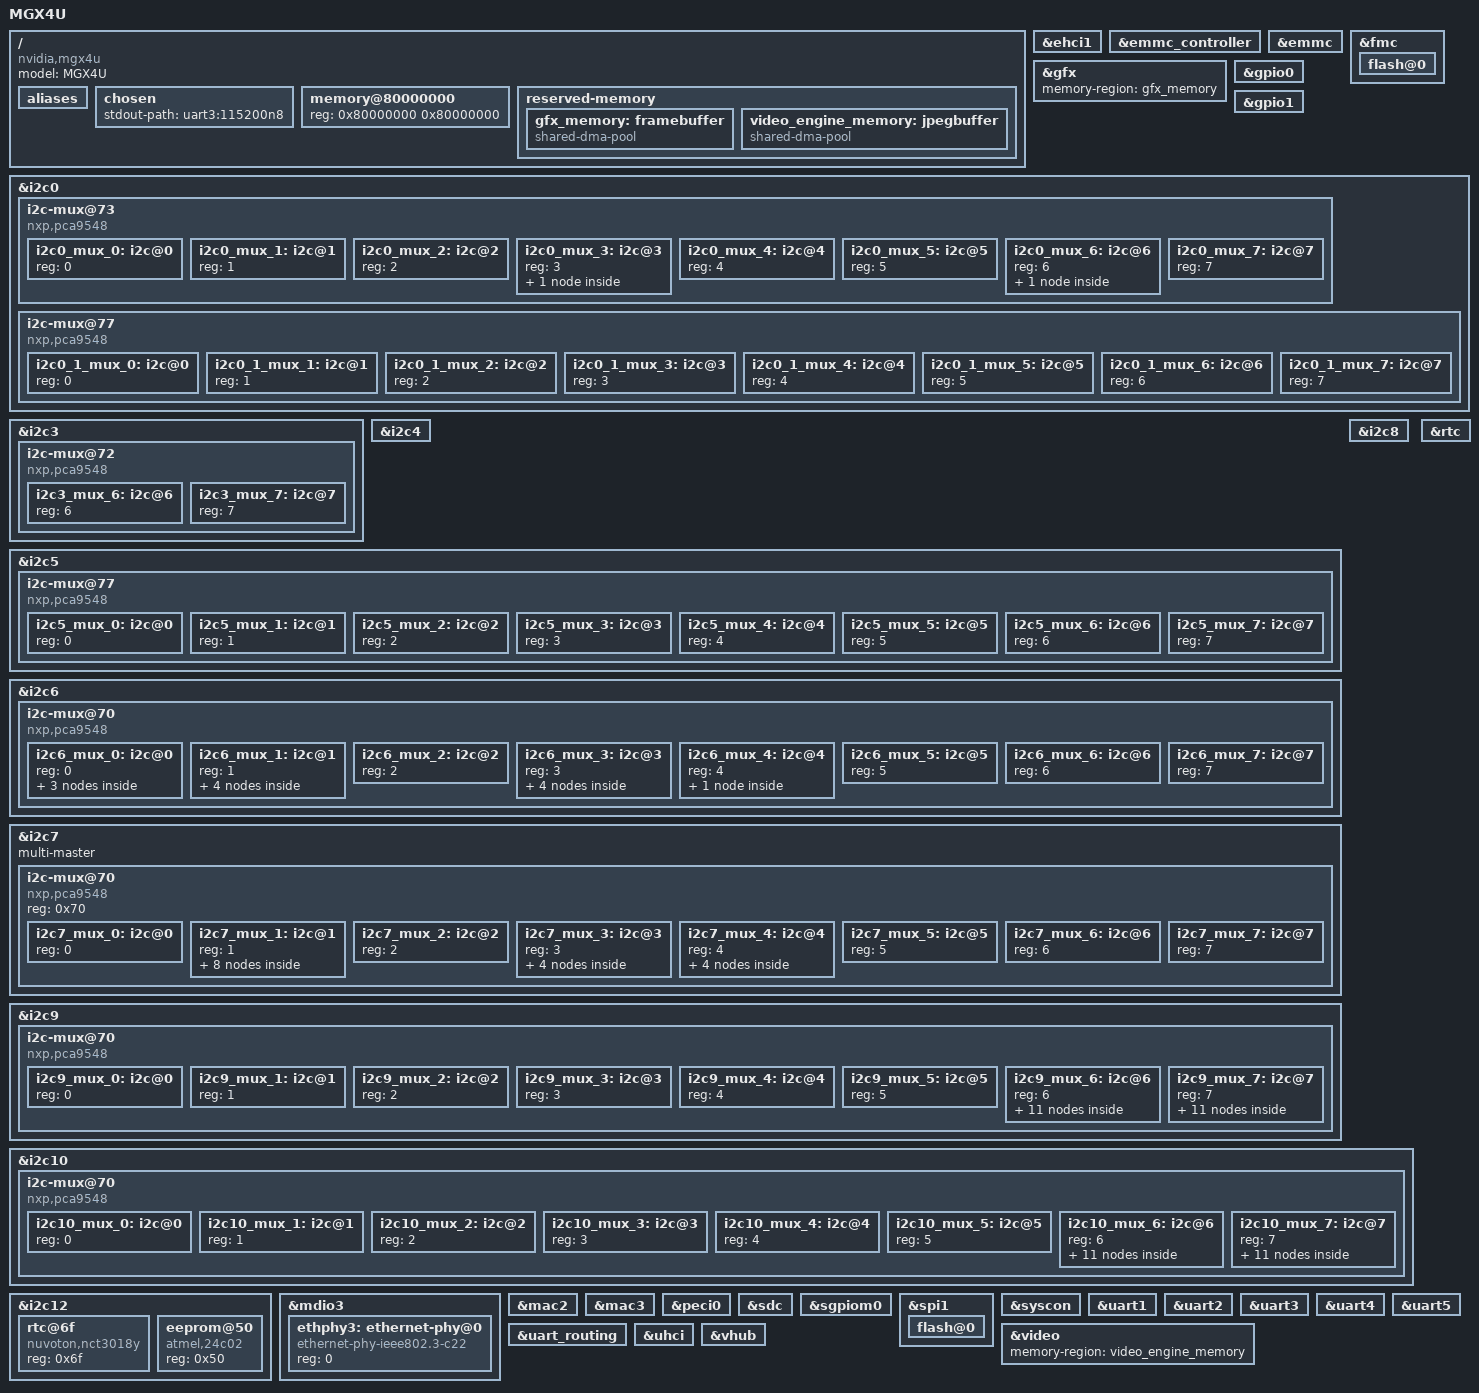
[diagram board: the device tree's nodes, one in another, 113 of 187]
// SPDX-License-Identifier: GPL-2.0

/dts-v1/;

#include "aspeed-g6.dtsi"
#include <dt-bindings/gpio/aspeed-gpio.h>
#include <dt-bindings/i2c/i2c.h>

/ {
	model = "MGX4U";
	compatible = "nvidia,mgx4u", "aspeed,ast2600";

	aliases {
		serial0 = &uart1;
		serial1 = &uart2;
		serial2 = &uart3;
		serial3 = &uart4;
		serial4 = &uart5;

		i2c16 = &i2c5_mux_0;
		i2c17 = &i2c5_mux_1;
		i2c18 = &i2c5_mux_2;
		i2c19 = &i2c5_mux_3;
		i2c20 = &i2c5_mux_4;
		i2c21 = &i2c5_mux_5;
		i2c22 = &i2c5_mux_6;
		i2c23 = &i2c5_mux_7;

		i2c24 = &i2c6_mux_0;
		i2c25 = &i2c6_mux_1;
		i2c26 = &i2c6_mux_2;
		i2c27 = &i2c6_mux_3;
		i2c28 = &i2c6_mux_4;
		i2c29 = &i2c6_mux_5;
		i2c30 = &i2c6_mux_6;
		i2c31 = &i2c6_mux_7;

		i2c32 = &i2c7_1_mux_0;
		i2c33 = &i2c7_1_mux_1;
		i2c35 = &i2c7_1_mux_2;
		i2c36 = &i2c7_1_mux_3;
		i2c37 = &i2c7_mux_0;
		i2c38 = &i2c7_mux_1;
		i2c39 = &i2c7_mux_2;
		i2c40 = &i2c7_mux_3;
		i2c41 = &i2c7_mux_4;
		i2c42 = &i2c7_mux_5;
		i2c43 = &i2c7_mux_6;
		i2c44 = &i2c7_mux_7;

		i2c45 = &i2c0_mux_0;
		i2c46 = &i2c0_mux_1;
		i2c47 = &i2c0_mux_2;
		i2c48 = &i2c0_mux_3;
		i2c49 = &i2c0_mux_4;
		i2c50 = &i2c0_mux_5;
		i2c51 = &i2c0_mux_6;
		i2c52 = &i2c0_mux_7;

		i2c53 = &i2c0_1_mux_0;
		i2c54 = &i2c0_1_mux_1;
		i2c55 = &i2c0_1_mux_2;
		i2c56 = &i2c0_1_mux_3;
		i2c57 = &i2c0_1_mux_4;
		i2c58 = &i2c0_1_mux_5;
		i2c59 = &i2c0_1_mux_6;
		i2c60 = &i2c0_1_mux_7;

		i2c61 = &i2c3_mux_6;
		i2c62 = &i2c3_mux_7;

		i2c63 = &i2c9_mux_0;
		i2c64 = &i2c9_mux_1;
		i2c65 = &i2c9_mux_2;
		i2c66 = &i2c9_mux_3;
		i2c67 = &i2c9_mux_4;
		i2c68 = &i2c9_mux_5;
		i2c69 = &i2c9_mux_6;
		i2c70 = &i2c9_mux_7;

		i2c71 = &i2c9_mux_6_2;
		i2c72 = &i2c9_mux_6_3;
		i2c73 = &i2c9_mux_7_2;
		i2c74 = &i2c9_mux_7_3;
		i2c75 = &i2c10_mux_6_2;
		i2c76 = &i2c10_mux_6_3;
		i2c77 = &i2c10_mux_7_2;
		i2c78 = &i2c10_mux_7_3;
	};

	chosen {
		stdout-path = "uart3:115200n8";
	};

	memory@80000000 {
		device_type = "memory";
		reg = <0x80000000 0x80000000>;
	};

	reserved-memory {
		#address-cells = <1>;
		#size-cells = <1>;
		ranges;

		gfx_memory: framebuffer {
			size = <0x01000000>;
			alignment = <0x01000000>;
			compatible = "shared-dma-pool";
			reusable;
		};

		video_engine_memory: jpegbuffer {
			size = <0x02000000>;	/* 32M */
			alignment = <0x01000000>;
			compatible = "shared-dma-pool";
			reusable;
		};
	};
};

&ehci1 {
	status = "okay";
};

&emmc_controller {
	status = "okay";
};

&emmc {
	non-removable;
	bus-width = <4>;
	max-frequency = <100000000>;
	clk-phase-mmc-hs200 = <9>, <225>;
};

&fmc {
	status = "okay";

	flash@0 {
		status = "okay";
		m25p,fast-read;
		label = "bmc";
		spi-rx-bus-width = <4>;
		spi-tx-bus-width = <4>;
		spi-max-frequency = <50000000>;
#include "openbmc-flash-layout-128.dtsi"
	};
};

&gfx {
	memory-region = <&gfx_memory>;
	status = "okay";
};

&gpio0 {
	gpio-line-names =
	/*A0-A7*/ "","","","","","","","",
	/*B0-B7*/ "","","","","","","","RST_BMC_8211F_N",
	/*C0-C7*/ "","","","","","","","",
	/*D0-D7*/ "","","","","","","","",
	/*E0-E7*/ "","","","","","","","",
	/*F0-F7*/ "","RST_BIOSROM_1_BMC_N","","RST_SPI_PFRM1_R_N","","","SPI_BIOS_MUX_SEL","",
	/*G0-G7*/ "","","","","","","","",
	/*H0-H7*/ "","","","","","","","",
	/*I0-I7*/ "","","","","","","","",
	/*J0-J7*/ "","","","","","","","",
	/*K0-K7*/ "","","","","","","","",
	/*L0-L7*/ "","","","","","","","",
	/*M0-M7*/ "","","","","","","","",
	/*N0-N7*/ "","","","","","","","",
	/*O0-O7*/ "","","","","","","","",
	/*P0-P7*/ "","","","","","","","",
	/*Q0-Q7*/ "","","","","","","","",
	/*R0-R7*/ "","","","","","","","",
	/*S0-S7*/ "","","","","","","","",
	/*T0-T7*/ "","","","","","","","",
	/*U0-U7*/ "","","","","","","","",
	/*V0-V7*/ "","","SCM_HPM_STBY_RST_N","","SCM_HPM_STBY_EN","","","",
	/*W0-W7*/ "","","","","","","","",
	/*X0-X7*/ "","","","","","","","",
	/*Y0-Y7*/ "","","","","","","","",
	/*Z0-Z7*/ "","","","","","","","";
	status = "okay";
};

&gpio1 {
	gpio-line-names =
	/*18A0-18A7*/ "","","","","","","","",
	/*18B0-18B7*/ "","","","","SW_MAIN_EN","HOST_GLOBAL_WP_N","","",
	/*18C0-18C7*/ "","","","","","","","",
	/*18D0-18D7*/ "","","","","","","","",
	/*18E0-18E3*/ "","","","";
	status = "okay";
};

&i2c0 {
	status = "okay";

	i2c-mux@73 {
		compatible = "nxp,pca9548";
		reg = <0x73>;
		#address-cells = <1>;
		#size-cells = <0>;
		i2c-mux-idle-disconnect;

		i2c0_mux_0: i2c@0 {
			reg = <0>;
			#address-cells = <1>;
			#size-cells = <0>;
		};

		i2c0_mux_1: i2c@1 {
			#address-cells = <1>;
			#size-cells = <0>;
			reg = <1>;
		};

		i2c0_mux_2: i2c@2 {
			reg = <2>;
			#address-cells = <1>;
			#size-cells = <0>;
		};

		i2c0_mux_3: i2c@3 {
			reg = <3>;
			#address-cells = <1>;
			#size-cells = <0>;

			eeprom@51 {
				compatible = "atmel,24c02";
				reg = <0x51>;
			};
		};

		i2c0_mux_4: i2c@4 {
			reg = <4>;
			#address-cells = <1>;
			#size-cells = <0>;
		};

		i2c0_mux_5: i2c@5 {
			reg = <5>;
			#address-cells = <1>;
			#size-cells = <0>;
		};

		i2c0_mux_6: i2c@6 {
			reg = <6>;
			#address-cells = <1>;
			#size-cells = <0>;

			temperature-sensor@4c {
				compatible = "ti,tmp75";
				reg = <0x4c>;
			};
		};

		i2c0_mux_7: i2c@7 {
			reg = <7>;
			#address-cells = <1>;
			#size-cells = <0>;
		};
	};

	i2c-mux@77 {
		compatible = "nxp,pca9548";
		reg = <0x77>;
		#address-cells = <1>;
		#size-cells = <0>;
		i2c-mux-idle-disconnect;

		i2c0_1_mux_0: i2c@0 {
			reg = <0>;
			#address-cells = <1>;
			#size-cells = <0>;
		};

		i2c0_1_mux_1: i2c@1 {
			reg = <1>;
			#address-cells = <1>;
			#size-cells = <0>;
		};

		i2c0_1_mux_2: i2c@2 {
			reg = <2>;
			#address-cells = <1>;
			#size-cells = <0>;
		};

		i2c0_1_mux_3: i2c@3 {
			reg = <3>;
			#address-cells = <1>;
			#size-cells = <0>;
		};

		i2c0_1_mux_4: i2c@4 {
			reg = <4>;
			#address-cells = <1>;
			#size-cells = <0>;
		};

		i2c0_1_mux_5: i2c@5 {
			reg = <5>;
			#address-cells = <1>;
			#size-cells = <0>;
		};

		i2c0_1_mux_6: i2c@6 {
			reg = <6>;
			#address-cells = <1>;
			#size-cells = <0>;
		};

		i2c0_1_mux_7: i2c@7 {
			reg = <7>;
			#address-cells = <1>;
			#size-cells = <0>;
		};
	};
};


&i2c3 {
	status = "okay";

	i2c-mux@72 {
		compatible = "nxp,pca9548";
		reg = <0x72>;
		#address-cells = <1>;
		#size-cells = <0>;
		i2c-mux-idle-disconnect;

		i2c3_mux_6: i2c@6 {
			reg = <6>;
			#address-cells = <1>;
			#size-cells = <0>;
		};

		i2c3_mux_7: i2c@7 {
			reg = <7>;
			#address-cells = <1>;
			#size-cells = <0>;
		};
	};
};

&i2c4 {
	status = "okay";
};

&i2c5 {
	status = "okay";

	i2c-mux@77 {
		compatible = "nxp,pca9548";
		reg = <0x77>;
		#address-cells = <1>;
		#size-cells = <0>;
		i2c-mux-idle-disconnect;

		i2c5_mux_0: i2c@0 {
			reg = <0>;
			#address-cells = <1>;
			#size-cells = <0>;
		};

		i2c5_mux_1: i2c@1 {
			reg = <1>;
			#address-cells = <1>;
			#size-cells = <0>;
		};

		i2c5_mux_2: i2c@2 {
			reg = <2>;
			#address-cells = <1>;
			#size-cells = <0>;
		};

		i2c5_mux_3: i2c@3 {
			reg = <3>;
			#address-cells = <1>;
			#size-cells = <0>;
		};

		i2c5_mux_4: i2c@4 {
			reg = <4>;
			#address-cells = <1>;
			#size-cells = <0>;
		};

		i2c5_mux_5: i2c@5 {
			reg = <5>;
			#address-cells = <1>;
			#size-cells = <0>;
		};

		i2c5_mux_6: i2c@6 {
			reg = <6>;
			#address-cells = <1>;
			#size-cells = <0>;
		};

		i2c5_mux_7: i2c@7 {
			reg = <7>;
			#address-cells = <1>;
			#size-cells = <0>;
		};
	};
};

&i2c6 {
	status = "okay";

	i2c-mux@70 {
		reg = <0x70>;
		compatible = "nxp,pca9548";
		#address-cells = <1>;
		#size-cells = <0>;
		i2c-mux-idle-disconnect;

		i2c6_mux_0: i2c@0 {
			reg = <0>;
			#address-cells = <1>;
			#size-cells = <0>;

			temperature-sensor@4a {
				compatible = "ti,tmp75";
				reg = <0x4a>;
			};

			temperature-sensor@4b {
				compatible = "ti,tmp75";
				reg = <0x4b>;
			};

			eeprom@51 {
				compatible = "atmel,24c64";
				reg = <0x51>;
				pagesize = <32>;
			};
		};

		i2c6_mux_1: i2c@1 {
			reg = <1>;
			#address-cells = <1>;
			#size-cells = <0>;

			/*fan controller 0*/
			fan-controller@20 {
				compatible = "maxim,max31790";
				reg = <0x20>;
			};

			/*fan controller 1*/
			fan-controller@21 {
				compatible = "maxim,max31790";
				reg = <0x21>;
			};

			eeprom@57 {
				compatible = "atmel,24c64";
				reg = <0x57>;
				pagesize = <32>;
			};

			hpmfanio: gpio@27 {
				compatible = "nxp,pca9555";
				reg = <0x27>;
				gpio-controller;
				#gpio-cells = <2>;
				interrupt-controller;
				#interrupt-cells = <2>;
				interrupt-parent = <&gpio0>;
				interrupts = <11 0>;
				gpio-line-names =
						"HPM_FAN1_INSTALL", "HPM_FAN2_INSTALL",
						"HPM_FAN3_INSTALL", "HPM_FAN4_INSTALL",
						"HPM_FAN5_INSTALL", "",
						"","";
			};
		 };

		 i2c6_mux_2: i2c@2 {
			reg = <2>;
			#address-cells = <1>;
			#size-cells = <0>;
		 };

		 i2c6_mux_3: i2c@3 {
			reg = <3>;
			#address-cells = <1>;
			#size-cells = <0>;

			/* 4056 fan board_EEPROM*/
			eeprom@57 {
				compatible = "atmel,24c64";
				reg = <0x57>;
				pagesize = <32>;
			};

			/*fan controller 0*/
			fan-controller@20 {
				compatible = "maxim,max31790";
				reg = <0x20>;
			};
			/*fan controller 1*/
			fan-controller@21 {
				compatible = "maxim,max31790";
				reg = <0x21>;
			};

			gpufanio: gpio@27 {
				compatible = "nxp,pca9555";
				reg = <0x27>;
				gpio-controller;
				#gpio-cells = <2>;
				interrupt-controller;
				#interrupt-cells = <2>;
				interrupt-parent = <&gpio0>;
				interrupts = <11 0>;
				gpio-line-names =
						"GPU_FAN1_INSTALL", "GPU_FAN2_INSTALL",
						"GPU_FAN3_INSTALL", "GPU_FAN4_INSTALL",
						"GPU_FAN5_INSTALL", "",
						"","";
			};
		 };

		i2c6_mux_4: i2c@4 {
			reg = <4>;
			#address-cells = <1>;
			#size-cells = <0>;

			/* IO board EEPROM*/
			eeprom@57 {
				compatible = "atmel,24c64";
				reg = <0x57>;
				pagesize = <32>;
			};
		};

		i2c6_mux_5: i2c@5 {
			reg = <5>;
			#address-cells = <1>;
			#size-cells = <0>;
		};

		i2c6_mux_6: i2c@6 {
			reg = <6>;
			#address-cells = <1>;
			#size-cells = <0>;
		};

		i2c6_mux_7: i2c@7 {
			reg = <7>;
			#address-cells = <1>;
			#size-cells = <0>;
		};
	};
};

&i2c7 {
	multi-master;
	status = "okay";

	i2c-mux@70 {
		compatible = "nxp,pca9548";
		reg = <0x70>;
		#address-cells = <1>;
		#size-cells = <0>;

		i2c7_mux_0: i2c@0 {
			reg = <0>;
			#address-cells = <1>;
			#size-cells = <0>;
		};

		i2c7_mux_1: i2c@1 {
			reg = <1>;
			#address-cells = <1>;
			#size-cells = <0>;

			i2c-mux@71 {
				compatible = "nxp,pca9545";
				reg = <0x71>;
				#address-cells = <1>;
				#size-cells = <0>;

				i2c7_1_mux_0: i2c@0 {
					reg = <0>;
					#address-cells = <1>;
					#size-cells = <0>;
				};

				i2c7_1_mux_1: i2c@1 {
					reg = <1>;
					#address-cells = <1>;
					#size-cells = <0>;

					eeprom@55 {
						compatible = "atmel,24c64";
						reg = <0x55>;
						pagesize = <32>;
					};

					eeprom@50 {
						compatible = "atmel,24c02";
						reg = <0x50>;
						pagesize = <32>;
					};

					eeprom@53 {
						compatible = "atmel,24c02";
						reg = <0x53>;
						pagesize = <32>;
					};
				};

				i2c7_1_mux_2: i2c@2 {
					reg = <2>;
					#address-cells = <1>;
					#size-cells = <0>;
				};

				i2c7_1_mux_3: i2c@3 {
					reg = <3>;
					#address-cells = <1>;
					#size-cells = <0>;
				};
			};
		};

		i2c7_mux_2: i2c@2 {
			reg = <2>;
			#address-cells = <1>;
			#size-cells = <0>;
		};

		i2c7_mux_3: i2c@3 {
			reg = <3>;
			#address-cells = <1>;
			#size-cells = <0>;

			/* XDPE19284B - CPU0 PVCCIN VR */
			regulator@60 {
				compatible = "infineon,xdpe152c4";
				reg = <0x60>;
			};

			/* XDPE19284B - CPU0 PVCCFA EHV FIVRA / PVCCINF_VR*/
			regulator@62 {
				compatible = "infineon,xdpe152c4";
				reg = <0x62>;
			};

			/* XDPE19284B - CPU0 PVCCA EHV PVCCIN VR */
			regulator@74 {
				compatible = "infineon,xdpe152c4";
				reg = <0x74>;
			};

			/* XDPE19284B - CPU0 PVVCCD0 & D1 VR */
			regulator@76 {
				compatible = "infineon,xdpe152c4";
				reg = <0x76>;
			};
		};

		i2c7_mux_4: i2c@4 {
			reg = <4>;
			#address-cells = <1>;
			#size-cells = <0>;

			/* XDPE19284B - CPU1 PVCCIN VR */
			regulator@60 {
				compatible = "infineon,xdpe152c4";
				reg = <0x60>;
			};

			/* XDPE19284B - CPU1 PVCCFA EHV FIVRA / PVCCINF_VR*/
			regulator@62 {
				compatible = "infineon,xdpe152c4";
				reg = <0x62>;
			};

			/* XDPE19284B - CPU1 PVCCA EHV PVCCIN VR */
			regulator@74 {
				compatible = "infineon,xdpe152c4";
				reg = <0x74>;
			};

			/* XDPE19284B - CPU1 PVVCCD0 & D1 VR */
			regulator@76 {
				compatible = "infineon,xdpe152c4";
				reg = <0x76>;
			};
		};

		i2c7_mux_5: i2c@5 {
			reg = <5>;
			#address-cells = <1>;
			#size-cells = <0>;
		};

		i2c7_mux_6: i2c@6 {
			reg = <6>;
			#address-cells = <1>;
			#size-cells = <0>;
		};

		i2c7_mux_7: i2c@7 {
			reg = <7>;
			#address-cells = <1>;
			#size-cells = <0>;
		};
	};
};

&i2c8 {
	status = "okay";
};

&i2c9 {
	status = "okay";

	i2c-mux@70 {
		compatible = "nxp,pca9548";
		reg = <0x70>;
		#address-cells = <1>;
		#size-cells = <0>;
		i2c-mux-idle-disconnect;

		i2c9_mux_0: i2c@0 {
			reg = <0>;
			#address-cells = <1>;
			#size-cells = <0>;
		};

		i2c9_mux_1: i2c@1 {
			reg = <1>;
			#address-cells = <1>;
			#size-cells = <0>;
		};

		i2c9_mux_2: i2c@2 {
			reg = <2>;
			#address-cells = <1>;
			#size-cells = <0>;
		};

		i2c9_mux_3: i2c@3 {
			reg = <3>;
			#address-cells = <1>;
			#size-cells = <0>;
		};

		i2c9_mux_4: i2c@4 {
			reg = <4>;
			#address-cells = <1>;
			#size-cells = <0>;
		};

		i2c9_mux_5: i2c@5 {
			reg = <5>;
			#address-cells = <1>;
			#size-cells = <0>;
		};

		i2c9_mux_6: i2c@6 {
			reg = <6>;
			#address-cells = <1>;
			#size-cells = <0>;

			eeprom@56 {
				compatible = "atmel,24c128";
				reg = <0x56>;
			};

			gpio@26 {
				compatible = "nxp,pca9555";
				reg = <0x26>;
				gpio-controller;
				#gpio-cells = <2>;
				gpio-line-names = "WP_QSPI_CX0", "RST_SEQ_CX0_L",
						  "BOOT_COMPLT_CX0", "FNP_CX0_L",
						  "WP_FRU_CX0", "OVT_SHUTDOWN_CX0",
						  "", "",
						  "", "",
						  "TMP_WARNING_CX0", "USB_HUB1_RST_L",
						  "I2C_SWITCH1_RESET", "MCU1_GPIO",
						  "MCU1_RST_N", "MCU1_RECOVERY_N";

			};

			i2c-mux@72 {
				compatible = "nxp,pca9546";
				reg = <0x72>;
				i2c-mux-idle-disconnect;
				#address-cells = <1>;
				#size-cells = <0>;

				i2c@0 {
					reg = <0>;
					#address-cells = <1>;
					#size-cells = <0>;
				};

				i2c@1 {
					reg = <1>;
					#address-cells = <1>;
					#size-cells = <0>;
				};

				i2c9_mux_6_2: i2c@2 {
					reg = <2>;
					#address-cells = <1>;
					#size-cells = <0>;

					gpio@20 {
						reg = <0x20>;
						gpio-controller;
						compatible = "nxp,pca6408";
						#gpio-cells = <2>;
						gpio-line-names = "GLOBAL_WP_0",
								  "OOB_RST_N_0",
								  "OOB_RECOVERY_0",
								  "MCU_RECOVERY_N_0",
								  "MCU_RST_N_0",
								  "MCU_BYPASS_N_0",
								  "SMBUS_FRU_EEPROM_WP_0",
								  "";
					};

					eeprom@50 {
						reg = <0x50>;
						compatible = "atmel,24c128";
					};
				};

				i2c9_mux_6_3: i2c@3 {
					reg = <3>;
					#address-cells = <1>;
					#size-cells = <0>;

					gpio@20 {
						reg = <0x20>;
						gpio-controller;
						compatible = "nxp,pca6408";
						#gpio-cells = <2>;
						gpio-line-names = "GLOBAL_WP_1",
								  "OOB_RST_N_1",
								  "OOB_RECOVERY_1",
								  "MCU_RECOVERY_N_1",
								  "MCU_RST_N_1",
								  "MCU_BYPASS_N_1",
								  "SMBUS_FRU_EEPROM_WP_1",
								  "";
					};

					eeprom@50 {
						reg = <0x50>;
						compatible = "atmel,24c128";
					};
				};
			};
		};

		i2c9_mux_7: i2c@7 {
			reg = <7>;
			#address-cells = <1>;
			#size-cells = <0>;

			eeprom@56 {
				compatible = "atmel,24c128";
				reg = <0x56>;
			};

			gpio@26 {
				compatible = "nxp,pca9555";
				reg = <0x26>;
				gpio-controller;
				#gpio-cells = <2>;
				gpio-line-names = "WP_QSPI_CX1", "RST_SEQ_CX1_L",
						  "BOOT_CMPLT_CX1", "FNP_CX1_L",
						  "WP_FRU_CX1", "OVT_SHUTDOWN_CX1",
						  "TMP_WARNING_CX1", "USB_HUB2_RST_L",
						  "I2C_SWITCH2_RESET", "",
						  "", "",
						  "", "",
						  "", "";
			};

			i2c-mux@72 {
				compatible = "nxp,pca9546";
				reg = <0x72>;
				i2c-mux-idle-disconnect;
				#address-cells = <1>;
				#size-cells = <0>;

				i2c@0 {
					reg = <0>;
					#address-cells = <1>;
					#size-cells = <0>;
				};

				i2c@1 {
					reg = <1>;
					#address-cells = <1>;
					#size-cells = <0>;
				};

				i2c9_mux_7_2: i2c@2 {
					reg = <2>;
					#address-cells = <1>;
					#size-cells = <0>;

					gpio@20 {
						reg = <0x20>;
						gpio-controller;
						compatible = "nxp,pca6408";
						#gpio-cells = <2>;
						gpio-line-names = "GLOBAL_WP_2",
								  "OOB_RST_N_2",
								  "OOB_RECOVERY_2",
								  "MCU_RECOVERY_N_2",
								  "MCU_RST_N_2",
								  "MCU_BYPASS_N_2",
								  "SMBUS_FRU_EEPROM_WP_2",
								  "";
					};

					eeprom@50 {
						compatible = "atmel,24c128";
						reg = <0x50>;
					};
				};

				i2c9_mux_7_3: i2c@3 {
					reg = <3>;
					#address-cells = <1>;
					#size-cells = <0>;

					gpio@20 {
						reg = <0x20>;
						gpio-controller;
						compatible = "nxp,pca6408";
						#gpio-cells = <2>;
						gpio-line-names = "GLOBAL_WP_3",
								  "OOB_RST_N_3",
								  "OOB_RECOVERY_3",
								  "MCU_RECOVERY_N_3",
								  "MCU_RST_N_3",
								  "MCU_BYPASS_N_3",
								  "SMBUS_FRU_EEPROM_WP_3",
								  "";
					};

					eeprom@50 {
						compatible = "atmel,24c128";
						reg = <0x50>;
					};
				};
			};
		};
	};
};

&i2c10 {
	status = "okay";

	i2c-mux@70 {
		compatible = "nxp,pca9548";
		reg = <0x70>;
		#address-cells = <1>;
		#size-cells = <0>;
		i2c-mux-idle-disconnect;

		i2c10_mux_0: i2c@0 {
			reg = <0>;
			#address-cells = <1>;
			#size-cells = <0>;
		};

		i2c10_mux_1: i2c@1 {
			reg = <1>;
			#address-cells = <1>;
			#size-cells = <0>;
		};

		i2c10_mux_2: i2c@2 {
			reg = <2>;
			#address-cells = <1>;
			#size-cells = <0>;
		};

		i2c10_mux_3: i2c@3 {
			reg = <3>;
			#address-cells = <1>;
			#size-cells = <0>;
		};

		i2c10_mux_4: i2c@4 {
			reg = <4>;
			#address-cells = <1>;
			#size-cells = <0>;
		};

		i2c10_mux_5: i2c@5 {
			reg = <5>;
			#address-cells = <1>;
			#size-cells = <0>;
		};

		i2c10_mux_6: i2c@6 {
			reg = <6>;
			#address-cells = <1>;
			#size-cells = <0>;

			eeprom@56 {
				compatible = "atmel,24c128";
				reg = <0x56>;
			};

			gpio@26 {
				compatible = "nxp,pca9555";
				reg = <0x26>;
				gpio-controller;
				#gpio-cells = <2>;
				gpio-line-names = "WP_QSPI_CX2", "RST_SEQ_CX2_L",
						  "BOOT_COMPLT_CX2", "FNP_CX2_L",
						  "WP_FRU_CX2", "OVT_SHUTDOWN_CX2",
						  "", "",
						  "", "",
						  "TMP_WARNING_CX2", "USB_HUB3_RST_L",
						  "I2C_SWITCH3_RESET", "MCU2_GPIO",
						  "MCU2_RST_N", "MCU2_RECOVERY_N";

			};

			i2c-mux@72 {
				compatible = "nxp,pca9546";
				reg = <0x72>;
				i2c-mux-idle-disconnect;
				#address-cells = <1>;
				#size-cells = <0>;

				i2c@0 {
					reg = <0>;
					#address-cells = <1>;
					#size-cells = <0>;
				};

				i2c@1 {
					reg = <1>;
					#address-cells = <1>;
					#size-cells = <0>;
				};

				i2c10_mux_6_2: i2c@2 {
					reg = <2>;
					#address-cells = <1>;
					#size-cells = <0>;

					gpio@20 {
						reg = <0x20>;
						gpio-controller;
						compatible = "nxp,pca6408";
						#gpio-cells = <2>;
						gpio-line-names = "GLOBAL_WP_4",
								  "OOB_RST_N_4",
								  "OOB_RECOVERY_4",
								  "MCU_RECOVERY_N_4",
								  "MCU_RST_N_4",
								  "MCU_BYPASS_N_4",
								  "SMBUS_FRU_EEPROM_WP_4",
								  "";
					};

					eeprom@50 {
						reg = <0x50>;
						compatible = "atmel,24c128";
					};
				};

				i2c10_mux_6_3: i2c@3 {
					reg = <3>;
					#address-cells = <1>;
					#size-cells = <0>;
					gpio@20 {
						reg = <0x20>;
						gpio-controller;
						compatible = "nxp,pca6408";
						#gpio-cells = <2>;
						gpio-line-names = "GLOBAL_WP_5",
								  "OOB_RST_N_5",
								  "OOB_RECOVERY_5",
								  "MCU_RECOVERY_N_5",
								  "MCU_RST_N_5",
								  "MCU_BYPASS_N_5",
								  "SMBUS_FRU_EEPROM_WP_5",
								  "";
					};

					eeprom@50 {
						reg = <0x50>;
						compatible = "atmel,24c128";
					};
				};
			};

		};

		i2c10_mux_7: i2c@7 {
			reg = <7>;
			#address-cells = <1>;
			#size-cells = <0>;

			eeprom@56 {
				compatible = "atmel,24c128";
				reg = <0x56>;
			};

			gpio@26 {
				compatible = "nxp,pca9555";
				reg = <0x26>;
				gpio-controller;
				#gpio-cells = <2>;
				gpio-line-names = "WP_QSPI_CX3", "RST_SEQ_CX3_L",
						  "BOOT_CMPLT_CX3", "FNP_CX3_L",
						  "WP_FRU_CX3", "OVT_SHUTDOWN_CX3",
						  "TMP_WARNING_CX3", "USB_HUB4_RST_L",
						  "I2C_SWITCH4_RESET", "",
						  "", "",
						  "", "",
						  "", "";
			};

			i2c-mux@72 {
				compatible = "nxp,pca9546";
				reg = <0x72>;
				i2c-mux-idle-disconnect;
				#address-cells = <1>;
				#size-cells = <0>;

				i2c@0 {
					reg = <0>;
					#address-cells = <1>;
					#size-cells = <0>;
				};

				i2c@1 {
					reg = <1>;
					#address-cells = <1>;
					#size-cells = <0>;
				};

				i2c10_mux_7_2: i2c@2 {
					reg = <2>;
					#address-cells = <1>;
					#size-cells = <0>;

					gpio@20 {
						reg = <0x20>;
						gpio-controller;
						compatible = "nxp,pca6408";
						#gpio-cells = <2>;
						gpio-line-names = "GLOBAL_WP_6",
								  "OOB_RST_N_6",
								  "OOB_RECOVERY_6",
								  "MCU_RECOVERY_N_6",
								  "MCU_RST_N_6",
								  "MCU_BYPASS_N_6",
								  "SMBUS_FRU_EEPROM_WP_6",
								  "";
					};

					eeprom@50 {
						compatible = "atmel,24c128";
						reg = <0x50>;
					};
				};

				i2c10_mux_7_3: i2c@3 {
					reg = <3>;
					#address-cells = <1>;
					#size-cells = <0>;

					gpio@20 {
						reg = <0x20>;
						gpio-controller;
						compatible = "nxp,pca6408";
						#gpio-cells = <2>;
						gpio-line-names = "GLOBAL_WP_7",
								  "OOB_RST_N_7",
								  "OOB_RECOVERY_7",
								  "MCU_RECOVERY_N_7",
								  "MCU_RST_N_7",
								  "MCU_BYPASS_N_7",
								  "SMBUS_FRU_EEPROM_WP_7",
								  "";
					};

					eeprom@50 {
						compatible = "atmel,24c128";
						reg = <0x50>;
					};
				};
			};

		};
	};
};

&i2c12 {
	status = "okay";

	rtc@6f {
		compatible = "nuvoton,nct3018y";
		reg = <0x6f>;
	};

	eeprom@50 {
		compatible = "atmel,24c02";
		reg = <0x50>;
	};
};

&mdio3 {
	status = "okay";

	ethphy3: ethernet-phy@0 {
		compatible = "ethernet-phy-ieee802.3-c22";
		reg = <0>;
	};
};

&mac2 {
	pinctrl-names = "default";
	phy-mode = "rmii";
	pinctrl-0 = <&pinctrl_rmii3_default>;
	use-ncsi;
	status = "okay";
};

&mac3 {
	phy-mode = "rgmii-id";
	phy-handle = <&ethphy3>;
	pinctrl-names = "default";
	pinctrl-0 = <&pinctrl_rgmii4_default>;
	status = "okay";
};

&peci0 {
	status = "okay";
};

&rtc {
	status = "okay";
};

&sdc {
	status = "okay";
};

&sgpiom0 {
	ngpios = <128>;
	gpio-line-names =
		"","LED_PORT80_0_N",
		"","LED_PORT80_1_N",
		"","LED_PORT80_2_N",
		"","LED_PORT80_3_N",
		"","LED_PORT80_4_N",
		"","LED_PORT80_5_N",
		"","LED_PORT80_6_N",
		"","LED_PORT80_7_N",
		"","CPLD_JTAG_OE_R_N",
		"","RST_PE_SLOT_I2C_MUX_N",
		"","ASSERT_CPU0_PROCHOT_N",
		"","ASSERT_CPU1_PROCHOT_N",
		"","BMC_CPU0_NMI_OUT_N",
		"","BMC_CPU1_NMI_OUT_N",
		"","CPLD_PWRBRK_N",
		"","SPD_SWITCH_CTRL_N",
		"","COM_DBG_MODE",
		"","RST_CPU0_RTCRST_PLD","",
		"EN_MON_VBAT","","BMC_RST_BTN_OUT",
		"","BMC_PWR_BTN_OUT",
		"","BMC_WAKE",
		"","CPU_FRBK_OUT",
		"","CPU0_BMC_INIT",
		"","CPU1_BMC_INIT",
		"","NCSI_BMC_CLK_EN",
		"","NCSI_OCP_CLK_EN",
		"","IRQ_CPU0_TPM",
		"","UART_HPM_MUX",
		"","DEBUG_BIT_0","","DEBUG_BIT_1",
		"","DEBUG_BIT_2",
		"FAN_4056_BOARD_ID_0","DEBUG_BIT_3",
		"FAN_4056_BOARD_ID_1","DEBUG_BIT_4",
		"FAN_4056_BOARD_ID_2","DEBUG_BIT_5",
		"FAN_4056_BOARD_ID_3","DEBUG_BIT_6",
		"FAN_8080_BOARD_ID_0","DEBUG_BIT_7",
		"FAN_8080_BOARD_ID_1","LED_BMC_HBLED_CPLD_N",
		"FAN_8080_BOARD_ID_2","LED_SYS_ALERT_CPLD",
		"FAN_8080_BOARD_ID_3","LED_PWR_YEL_CPLD",
		"FAN1_FRONT_TOP_INSTALL","",
		"FAN2_FRONT_TOP_INSTALL","",
		"FAN3_FRONT_TOP_INSTALL","",
		"FAN4_FRONT_TOP_INSTALL","",
		"FAN5_FRONT_TOP_INSTALL","",
		"","",
		"","",
		"","",
		"FAN9_REAR_INSTALL","",
		"FAN_FRONT_SW0_FAIL","",
		"FAN_REAR_SW0_FAIL","",
		"FAN1_FRONT_BOT_INSTALL","",
		"FAN2_FRONT_BOT_INSTALL","LED_UID_N",
		"FAN3_FRONT_BOT_INSTALL","",
		"FAN4_FRONT_BOT_INSTALL","",
		"FAN5_FRONT_BOT_INSTALL","SPI_MUX3_EN",
		"FAN1_REAR_INSTALL","SPI_MUX2_EN",
		"FAN2_REAR_INSTALL","SPI_MUX1_EN",
		"FAN3_REAR_INSTALL","SPI_MUX3_SEL",
		"FAN4_REAR_INSTALL","SPI_MUX2_SEL",
		"FAN5_REAR_INSTALL","SPI_MUX1_SEL",
		"FAN6_REAR_INSTALL","PDB_RST",
		"FAN7_REAR_INSTALL","PRE_STANDBY_DROP",
		"FAN8_REAR_INSTALL","",
		"MLB_BRD_SKU_ID0","",
		"MLB_BRD_SKU_ID1","",
		"MLB_BRD_SKU_ID2","",
		"MLB_BRD_SKU_ID3","",
		"MLB_BRD_REV_ID0","",
		"MLB_BRD_REV_ID1","",
		"M2_1_PRESENT","",
		"M2_2_PRESENT","",
		"M2_1_ALERT","",
		"PASSWORD_CLEAR","",
		"IRQ_PSYS_CRIT","",
		"LEAKAGE_MONITOR_ALERT","",
		"M2_2_ALERT","",
		"RST_BTN","",
		"PWR_BTN","",
		"","",
		"CPU1_MEM_VRHOT","",
		"CPU0_MEM_VRHOT","",
		"CPU1_VRHOT","",
		"CPU0_VRHOT","",
		"RST_PLTRST_MONITOR","",
		"CPU_SLP_S3","",
		"TPM_PRSNT","",
		"HPM_HMC_PCIE_PERST","",
		"CPU1_THERMTRIP","",
		"CPU0_THERMTRIP","",
		"CPU1_PROCHOT_CPLD","",
		"CPU0_PROCHOT_CPLD","",
		"CPU1_MEMTRIP","",
		"CPU0_MEMTRIP","",
		"CPU0_MEMHOT","",
		"CPU1_MEMHOT","",
		"CPU_ERR2","",
		"CPU_ERR1","",
		"CPU_ERR0","",
		"CPU_CATERR","",
		"CPU_RMCA","",
		"","",
		"CPU1_MON_FAIL","",
		"CPU0_MON_FAIL","",
		"PUS4_PRSNT_N","",
		"PUS5_PRSNT_N","",
		"PUS6_PRSNT_N","",
		"PUS7_PRSNT_N","",
		"PUS8_PRSNT_N","",
		"PUS9_PRSNT_N","",
		"PUS10_PRSNT_N","",
		"PUS11_PRSNT_N","",
		"PWRGD_CPU1_S0_PWROK","",
		"PWRGD_CPU0_S0_PWROK","",
		"","",
		"PSU_SMBUS_ALERT_N","",
		"PSU0_PRSNT_N","",
		"PSU1_PRSNT_N","",
		"PUS2_PRSNT_N","",
		"PUS3_PRSNT_N","",
		"CPU0_PRSNT_N","",
		"CPU1_PRSNT_N","",
		"CPU0_PWR_GOOD","",
		"CPU1_PWR_GOOD","",
		"PGD_SYS_PWROK","",
		"BIOS_POST_CMPLT_N","",
		"CPU0_CD_INIT_ERROR","",
		"CPU1_CD_INIT_ERROR","";
	status = "okay";
};

&spi1 {
	pinctrl-names = "default";
	pinctrl-0 = <&pinctrl_spi1_default>;
	fmc-spi-user-mode;
	status = "okay";

	flash@0 {
		m25p,fast-read;
		label = "bios";
		spi-max-frequency = <20000000>;
		spi-rx-bus-width = <2>;
		status = "okay";
	};
};

&syscon {
	status = "okay";
};

&uart1 {
	status = "okay";
};

&uart2 {
	status = "okay";
};

&uart3 {
	status = "okay";
};

&uart4 {
	status = "okay";
};

&uart5 {
	status = "okay";
};

&uart_routing {
	status = "okay";
};

&uhci {
	status = "okay";
};

&vhub {
	status = "okay";
};

&video {
	memory-region = <&video_engine_memory>;
	status = "okay";
};

